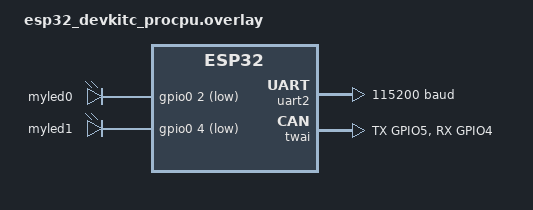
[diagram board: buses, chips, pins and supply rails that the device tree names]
/ {
    chosen {
        zephyr,canbus = &twai;
    };

    aliases {
        led0 = &myled0;
        led1 = &myled1;
        myuart2 = &uart2;
    };

    leds {
        compatible = "gpio-leds";

        myled0: led_0 {
            gpios = <&gpio0 2 GPIO_ACTIVE_LOW>;
        };

        myled1: led_1 {
            gpios = <&gpio0 4 GPIO_ACTIVE_LOW>;
        };
    };
};

&uart2 {
    status = "okay";
    current-speed = <115200>;
    pinctrl-0 = <&uart2_default>;
    pinctrl-names = "default";
};

&twai {
    status = "okay";
    pinctrl-0 = < &twai_default >;
    pinctrl-names = "default";
};

&pinctrl {
    twai_default: twai_default {
        group1 {
            pinmux = <TWAI_TX_GPIO5>;
        };

        group2 {
            pinmux = <TWAI_RX_GPIO4>;
        };
    };
};
